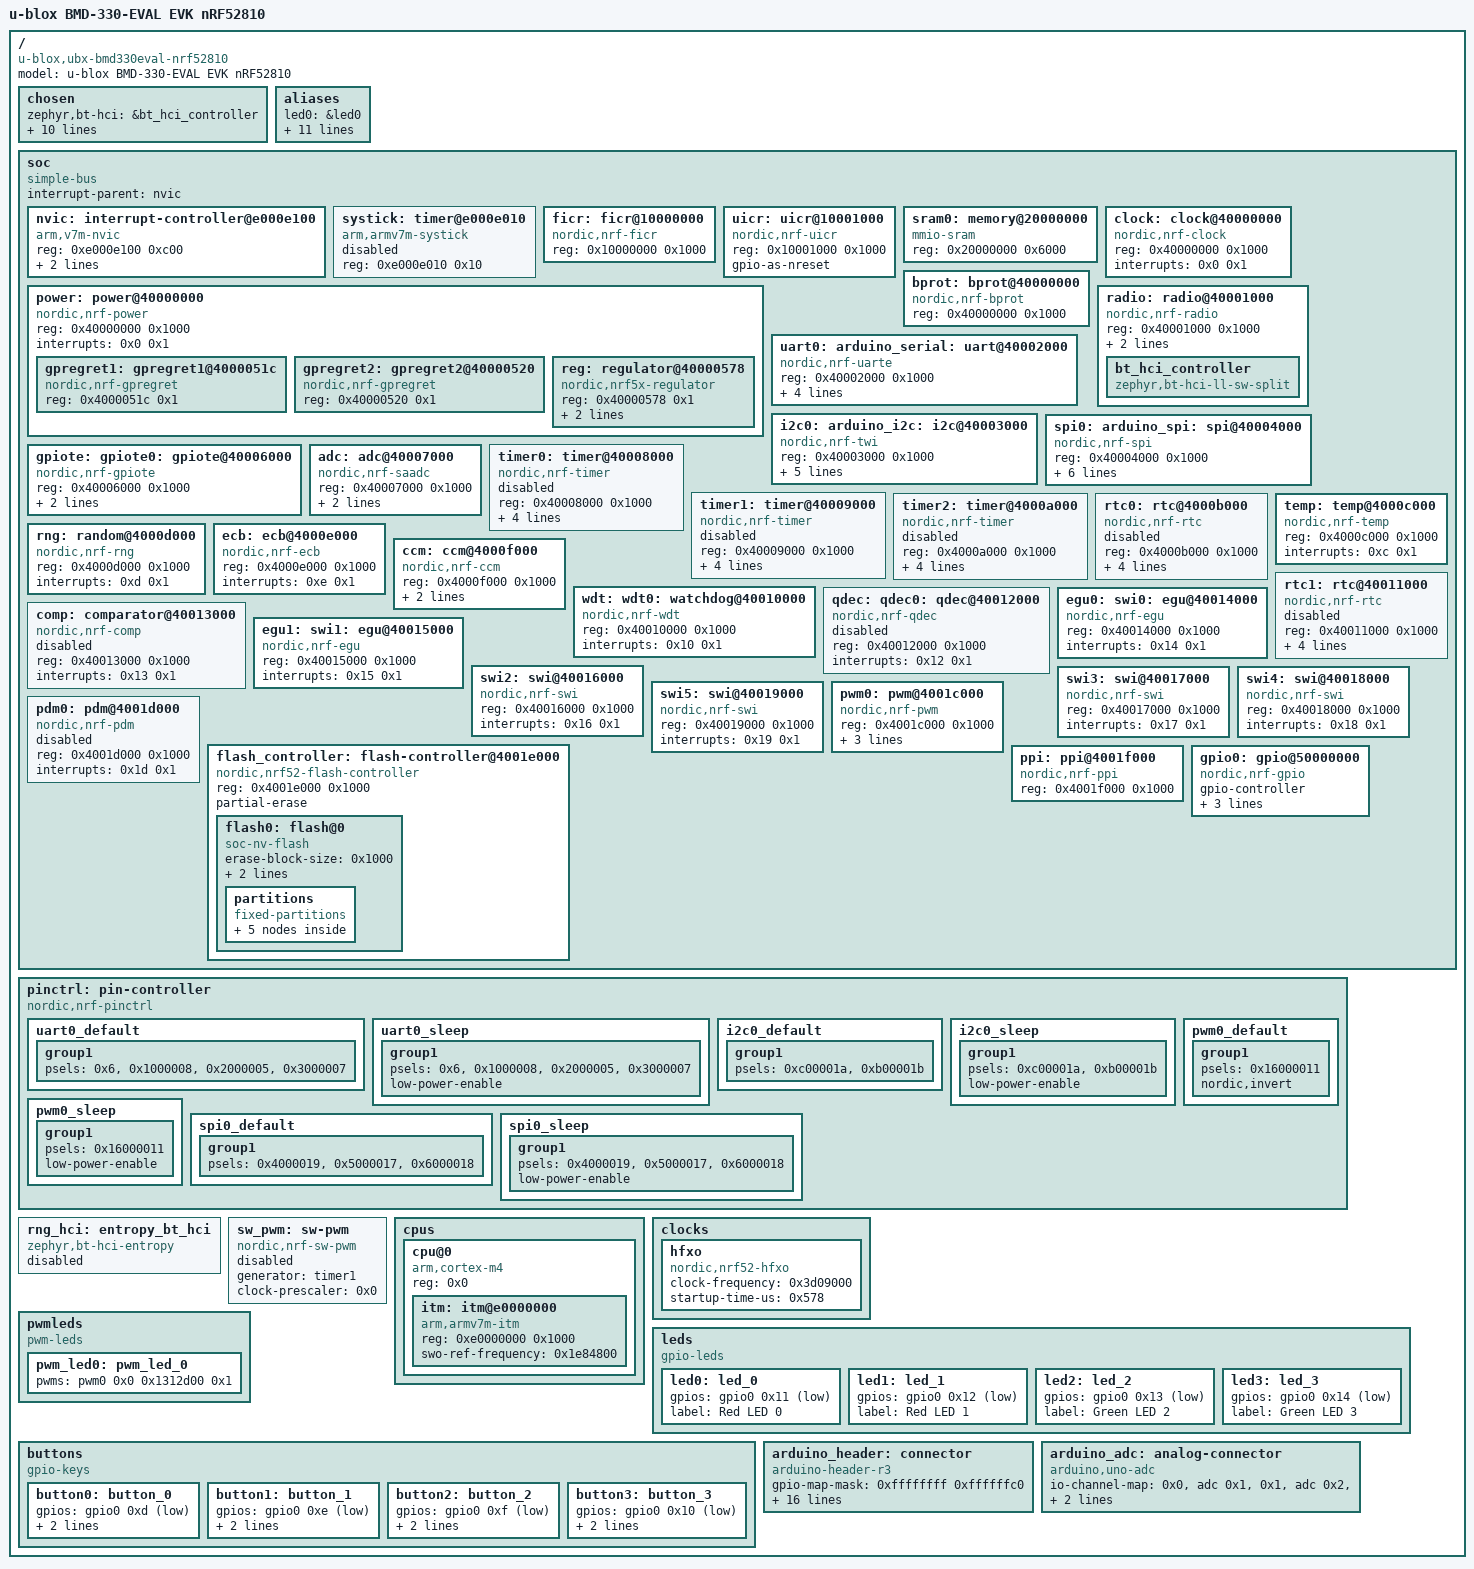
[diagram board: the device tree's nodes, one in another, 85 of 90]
/dts-v1/;

/* node '/' defined in zephyr/dts/common/skeleton.dtsi:9 */
/ {
	#address-cells = < 0x1 >;                      /* in zephyr/dts/common/skeleton.dtsi:10 */
	#size-cells = < 0x1 >;                         /* in zephyr/dts/common/skeleton.dtsi:11 */
	model = "u-blox BMD-330-EVAL EVK nRF52810";    /* in zephyr/boards/u-blox/ubx_bmd330eval/ubx_bmd330eval_nrf52810.dts:14 */
	compatible = "u-blox,ubx-bmd330eval-nrf52810"; /* in zephyr/boards/u-blox/ubx_bmd330eval/ubx_bmd330eval_nrf52810.dts:15 */

	/* node '/chosen' defined in zephyr/dts/common/skeleton.dtsi:13 */
	chosen {
		zephyr,bt-hci = &bt_hci_controller;          /* in zephyr/dts/arm/nordic/nrf52810.dtsi:10 */
		zephyr,entropy = &rng;                       /* in zephyr/dts/arm/nordic/nrf52810.dtsi:11 */
		zephyr,flash-controller = &flash_controller; /* in zephyr/dts/arm/nordic/nrf52810.dtsi:12 */
		zephyr,console = &uart0;                     /* in zephyr/boards/u-blox/ubx_bmd330eval/ubx_bmd330eval_nrf52810.dts:18 */
		zephyr,shell-uart = &uart0;                  /* in zephyr/boards/u-blox/ubx_bmd330eval/ubx_bmd330eval_nrf52810.dts:19 */
		zephyr,uart-mcumgr = &uart0;                 /* in zephyr/boards/u-blox/ubx_bmd330eval/ubx_bmd330eval_nrf52810.dts:20 */
		zephyr,bt-mon-uart = &uart0;                 /* in zephyr/boards/u-blox/ubx_bmd330eval/ubx_bmd330eval_nrf52810.dts:21 */
		zephyr,bt-c2h-uart = &uart0;                 /* in zephyr/boards/u-blox/ubx_bmd330eval/ubx_bmd330eval_nrf52810.dts:22 */
		zephyr,sram = &sram0;                        /* in zephyr/boards/u-blox/ubx_bmd330eval/ubx_bmd330eval_nrf52810.dts:23 */
		zephyr,flash = &flash0;                      /* in zephyr/boards/u-blox/ubx_bmd330eval/ubx_bmd330eval_nrf52810.dts:24 */
		zephyr,code-partition = &slot0_partition;    /* in zephyr/boards/u-blox/ubx_bmd330eval/ubx_bmd330eval_nrf52810.dts:25 */
	};

	/* node '/aliases' defined in zephyr/dts/common/skeleton.dtsi:15 */
	aliases {
		led0 = &led0;               /* in zephyr/boards/u-blox/ubx_bmd330eval/ubx_bmd330eval_nrf52810.dts:130 */
		led1 = &led1;               /* in zephyr/boards/u-blox/ubx_bmd330eval/ubx_bmd330eval_nrf52810.dts:131 */
		led2 = &led2;               /* in zephyr/boards/u-blox/ubx_bmd330eval/ubx_bmd330eval_nrf52810.dts:132 */
		led3 = &led3;               /* in zephyr/boards/u-blox/ubx_bmd330eval/ubx_bmd330eval_nrf52810.dts:133 */
		pwm-led0 = &pwm_led0;       /* in zephyr/boards/u-blox/ubx_bmd330eval/ubx_bmd330eval_nrf52810.dts:134 */
		sw0 = &button0;             /* in zephyr/boards/u-blox/ubx_bmd330eval/ubx_bmd330eval_nrf52810.dts:135 */
		sw1 = &button1;             /* in zephyr/boards/u-blox/ubx_bmd330eval/ubx_bmd330eval_nrf52810.dts:136 */
		sw2 = &button2;             /* in zephyr/boards/u-blox/ubx_bmd330eval/ubx_bmd330eval_nrf52810.dts:137 */
		sw3 = &button3;             /* in zephyr/boards/u-blox/ubx_bmd330eval/ubx_bmd330eval_nrf52810.dts:138 */
		mcuboot-button0 = &button0; /* in zephyr/boards/u-blox/ubx_bmd330eval/ubx_bmd330eval_nrf52810.dts:139 */
		mcuboot-led0 = &led0;       /* in zephyr/boards/u-blox/ubx_bmd330eval/ubx_bmd330eval_nrf52810.dts:140 */
		watchdog0 = &wdt0;          /* in zephyr/boards/u-blox/ubx_bmd330eval/ubx_bmd330eval_nrf52810.dts:141 */
	};

	/* node '/soc' defined in zephyr/dts/arm/armv7-m.dtsi:6 */
	soc {
		#address-cells = < 0x1 >;     /* in zephyr/dts/arm/armv7-m.dtsi:7 */
		#size-cells = < 0x1 >;        /* in zephyr/dts/arm/armv7-m.dtsi:8 */
		interrupt-parent = < &nvic >; /* in zephyr/dts/arm/armv7-m.dtsi:10 */
		ranges;                       /* in zephyr/dts/arm/armv7-m.dtsi:11 */
		compatible = "simple-bus";    /* in zephyr/dts/arm/nordic/nrf52810_qfaa.dtsi:21 */

		/* node '/soc/interrupt-controller@e000e100' defined in zephyr/dts/arm/armv7-m.dtsi:13 */
		nvic: interrupt-controller@e000e100 {
			#address-cells = < 0x1 >;            /* in zephyr/dts/arm/armv7-m.dtsi:14 */
			compatible = "arm,v7m-nvic";         /* in zephyr/dts/arm/armv7-m.dtsi:15 */
			reg = < 0xe000e100 0xc00 >;          /* in zephyr/dts/arm/armv7-m.dtsi:16 */
			interrupt-controller;                /* in zephyr/dts/arm/armv7-m.dtsi:17 */
			#interrupt-cells = < 0x2 >;          /* in zephyr/dts/arm/armv7-m.dtsi:18 */
			arm,num-irq-priority-bits = < 0x3 >; /* in zephyr/dts/arm/nordic/nrf52810.dtsi:377 */
			phandle = < 0x1 >;                   /* in zephyr/dts/arm/armv7-m.dtsi:10 */
		};

		/* node '/soc/timer@e000e010' defined in zephyr/dts/arm/armv7-m.dtsi:21 */
		systick: timer@e000e010 {
			compatible = "arm,armv7m-systick"; /* in zephyr/dts/arm/armv7-m.dtsi:22 */
			reg = < 0xe000e010 0x10 >;         /* in zephyr/dts/arm/armv7-m.dtsi:23 */
			status = "disabled";               /* in zephyr/dts/arm/nordic/nrf52810.dtsi:382 */
		};

		/* node '/soc/ficr@10000000' defined in zephyr/dts/arm/nordic/nrf52810.dtsi:44 */
		ficr: ficr@10000000 {
			compatible = "nordic,nrf-ficr"; /* in zephyr/dts/arm/nordic/nrf52810.dtsi:45 */
			reg = < 0x10000000 0x1000 >;    /* in zephyr/dts/arm/nordic/nrf52810.dtsi:46 */
			#nordic,ficr-cells = < 0x1 >;   /* in zephyr/dts/arm/nordic/nrf52810.dtsi:47 */
			status = "okay";                /* in zephyr/dts/arm/nordic/nrf52810.dtsi:48 */
		};

		/* node '/soc/uicr@10001000' defined in zephyr/dts/arm/nordic/nrf52810.dtsi:51 */
		uicr: uicr@10001000 {
			compatible = "nordic,nrf-uicr"; /* in zephyr/dts/arm/nordic/nrf52810.dtsi:52 */
			reg = < 0x10001000 0x1000 >;    /* in zephyr/dts/arm/nordic/nrf52810.dtsi:53 */
			status = "okay";                /* in zephyr/dts/arm/nordic/nrf52810.dtsi:54 */
			gpio-as-nreset;                 /* in zephyr/boards/u-blox/ubx_bmd330eval/ubx_bmd330eval_nrf52810.dts:154 */
		};

		/* node '/soc/memory@20000000' defined in zephyr/dts/arm/nordic/nrf52810.dtsi:57 */
		sram0: memory@20000000 {
			compatible = "mmio-sram";           /* in zephyr/dts/arm/nordic/nrf52810.dtsi:58 */
			#address-cells = < 0x1 >;           /* in zephyr/dts/arm/nordic/nrf52810.dtsi:59 */
			#size-cells = < 0x1 >;              /* in zephyr/dts/arm/nordic/nrf52810.dtsi:60 */
			reg = < 0x20000000 0x6000 >;        /* in zephyr/dts/arm/nordic/nrf52810_qfaa.dtsi:15 */
			ranges = < 0x0 0x20000000 0x6000 >; /* in zephyr/dts/arm/nordic/nrf52810_qfaa.dtsi:16 */
		};

		/* node '/soc/clock@40000000' defined in zephyr/dts/arm/nordic/nrf52810.dtsi:63 */
		clock: clock@40000000 {
			compatible = "nordic,nrf-clock"; /* in zephyr/dts/arm/nordic/nrf52810.dtsi:64 */
			reg = < 0x40000000 0x1000 >;     /* in zephyr/dts/arm/nordic/nrf52810.dtsi:65 */
			interrupts = < 0x0 0x1 >;        /* in zephyr/dts/arm/nordic/nrf52810.dtsi:66 */
			status = "okay";                 /* in zephyr/dts/arm/nordic/nrf52810.dtsi:67 */
		};

		/* node '/soc/power@40000000' defined in zephyr/dts/arm/nordic/nrf52810.dtsi:70 */
		power: power@40000000 {
			compatible = "nordic,nrf-power"; /* in zephyr/dts/arm/nordic/nrf52810.dtsi:71 */
			reg = < 0x40000000 0x1000 >;     /* in zephyr/dts/arm/nordic/nrf52810.dtsi:72 */
			interrupts = < 0x0 0x1 >;        /* in zephyr/dts/arm/nordic/nrf52810.dtsi:73 */
			status = "okay";                 /* in zephyr/dts/arm/nordic/nrf52810.dtsi:74 */
			#address-cells = < 0x1 >;        /* in zephyr/dts/arm/nordic/nrf52810.dtsi:75 */
			#size-cells = < 0x1 >;           /* in zephyr/dts/arm/nordic/nrf52810.dtsi:76 */

			/* node '/soc/power@40000000/gpregret1@4000051c' defined in zephyr/dts/arm/nordic/nrf52810.dtsi:78 */
			gpregret1: gpregret1@4000051c {
				#address-cells = < 0x1 >;           /* in zephyr/dts/arm/nordic/nrf52810.dtsi:79 */
				#size-cells = < 0x1 >;              /* in zephyr/dts/arm/nordic/nrf52810.dtsi:80 */
				compatible = "nordic,nrf-gpregret"; /* in zephyr/dts/arm/nordic/nrf52810.dtsi:81 */
				reg = < 0x4000051c 0x1 >;           /* in zephyr/dts/arm/nordic/nrf52810.dtsi:82 */
				status = "okay";                    /* in zephyr/dts/arm/nordic/nrf52810.dtsi:83 */
			};

			/* node '/soc/power@40000000/gpregret2@40000520' defined in zephyr/dts/arm/nordic/nrf52810.dtsi:86 */
			gpregret2: gpregret2@40000520 {
				#address-cells = < 0x1 >;           /* in zephyr/dts/arm/nordic/nrf52810.dtsi:87 */
				#size-cells = < 0x1 >;              /* in zephyr/dts/arm/nordic/nrf52810.dtsi:88 */
				compatible = "nordic,nrf-gpregret"; /* in zephyr/dts/arm/nordic/nrf52810.dtsi:89 */
				reg = < 0x40000520 0x1 >;           /* in zephyr/dts/arm/nordic/nrf52810.dtsi:90 */
				status = "okay";                    /* in zephyr/dts/arm/nordic/nrf52810.dtsi:91 */
			};

			/* node '/soc/power@40000000/regulator@40000578' defined in zephyr/dts/arm/nordic/nrf52810.dtsi:94 */
			reg: regulator@40000578 {
				compatible = "nordic,nrf5x-regulator"; /* in zephyr/dts/arm/nordic/nrf52810.dtsi:95 */
				reg = < 0x40000578 0x1 >;              /* in zephyr/dts/arm/nordic/nrf52810.dtsi:96 */
				regulator-name = "REG";                /* in zephyr/dts/arm/nordic/nrf52810.dtsi:97 */
				regulator-initial-mode = < 0x1 >;      /* in zephyr/boards/u-blox/ubx_bmd330eval/ubx_bmd330eval_nrf52810.dts:146 */
			};
		};

		/* node '/soc/bprot@40000000' defined in zephyr/dts/arm/nordic/nrf52810.dtsi:102 */
		bprot: bprot@40000000 {
			compatible = "nordic,nrf-bprot"; /* in zephyr/dts/arm/nordic/nrf52810.dtsi:103 */
			reg = < 0x40000000 0x1000 >;     /* in zephyr/dts/arm/nordic/nrf52810.dtsi:104 */
			status = "okay";                 /* in zephyr/dts/arm/nordic/nrf52810.dtsi:105 */
		};

		/* node '/soc/radio@40001000' defined in zephyr/dts/arm/nordic/nrf52810.dtsi:108 */
		radio: radio@40001000 {
			compatible = "nordic,nrf-radio"; /* in zephyr/dts/arm/nordic/nrf52810.dtsi:109 */
			reg = < 0x40001000 0x1000 >;     /* in zephyr/dts/arm/nordic/nrf52810.dtsi:110 */
			interrupts = < 0x1 0x1 >;        /* in zephyr/dts/arm/nordic/nrf52810.dtsi:111 */
			status = "okay";                 /* in zephyr/dts/arm/nordic/nrf52810.dtsi:112 */
			ble-2mbps-supported;             /* in zephyr/dts/arm/nordic/nrf52810.dtsi:113 */

			/* node '/soc/radio@40001000/bt_hci_controller' defined in zephyr/dts/arm/nordic/nrf52810.dtsi:118 */
			bt_hci_controller: bt_hci_controller {
				compatible = "zephyr,bt-hci-ll-sw-split"; /* in zephyr/dts/arm/nordic/nrf52810.dtsi:119 */
				status = "okay";                          /* in zephyr/dts/arm/nordic/nrf52810.dtsi:120 */
			};
		};

		/* node '/soc/uart@40002000' defined in zephyr/dts/arm/nordic/nrf52810.dtsi:124 */
		uart0: arduino_serial: uart@40002000 {
			reg = < 0x40002000 0x1000 >;     /* in zephyr/dts/arm/nordic/nrf52810.dtsi:128 */
			interrupts = < 0x2 0x1 >;        /* in zephyr/dts/arm/nordic/nrf52810.dtsi:129 */
			compatible = "nordic,nrf-uarte"; /* in zephyr/boards/u-blox/ubx_bmd330eval/ubx_bmd330eval_nrf52810.dts:166 */
			status = "okay";                 /* in zephyr/boards/u-blox/ubx_bmd330eval/ubx_bmd330eval_nrf52810.dts:167 */
			current-speed = < 0x1c200 >;     /* in zephyr/boards/u-blox/ubx_bmd330eval/ubx_bmd330eval_nrf52810.dts:168 */
			pinctrl-0 = < &uart0_default >;  /* in zephyr/boards/u-blox/ubx_bmd330eval/ubx_bmd330eval_nrf52810.dts:169 */
			pinctrl-1 = < &uart0_sleep >;    /* in zephyr/boards/u-blox/ubx_bmd330eval/ubx_bmd330eval_nrf52810.dts:170 */
			pinctrl-names = "default",
			                "sleep";         /* in zephyr/boards/u-blox/ubx_bmd330eval/ubx_bmd330eval_nrf52810.dts:171 */
		};

		/* node '/soc/i2c@40003000' defined in zephyr/dts/arm/nordic/nrf52810.dtsi:133 */
		i2c0: arduino_i2c: i2c@40003000 {
			#address-cells = < 0x1 >;      /* in zephyr/dts/arm/nordic/nrf52810.dtsi:142 */
			#size-cells = < 0x0 >;         /* in zephyr/dts/arm/nordic/nrf52810.dtsi:143 */
			reg = < 0x40003000 0x1000 >;   /* in zephyr/dts/arm/nordic/nrf52810.dtsi:144 */
			interrupts = < 0x3 0x1 >;      /* in zephyr/dts/arm/nordic/nrf52810.dtsi:145 */
			easydma-maxcnt-bits = < 0xa >; /* in zephyr/dts/arm/nordic/nrf52810.dtsi:146 */
			zephyr,pm-device-runtime-auto; /* in zephyr/dts/arm/nordic/nrf52810.dtsi:148 */
			compatible = "nordic,nrf-twi"; /* in zephyr/boards/u-blox/ubx_bmd330eval/ubx_bmd330eval_nrf52810.dts:175 */
			status = "okay";               /* in zephyr/boards/u-blox/ubx_bmd330eval/ubx_bmd330eval_nrf52810.dts:176 */
			pinctrl-0 = < &i2c0_default >; /* in zephyr/boards/u-blox/ubx_bmd330eval/ubx_bmd330eval_nrf52810.dts:177 */
			pinctrl-1 = < &i2c0_sleep >;   /* in zephyr/boards/u-blox/ubx_bmd330eval/ubx_bmd330eval_nrf52810.dts:178 */
			pinctrl-names = "default",
			                "sleep";       /* in zephyr/boards/u-blox/ubx_bmd330eval/ubx_bmd330eval_nrf52810.dts:179 */
		};

		/* node '/soc/spi@40004000' defined in zephyr/dts/arm/nordic/nrf52810.dtsi:151 */
		spi0: arduino_spi: spi@40004000 {
			#address-cells = < 0x1 >;                /* in zephyr/dts/arm/nordic/nrf52810.dtsi:160 */
			#size-cells = < 0x0 >;                   /* in zephyr/dts/arm/nordic/nrf52810.dtsi:161 */
			reg = < 0x40004000 0x1000 >;             /* in zephyr/dts/arm/nordic/nrf52810.dtsi:162 */
			interrupts = < 0x4 0x1 >;                /* in zephyr/dts/arm/nordic/nrf52810.dtsi:163 */
			max-frequency = < 0x7a1200 >;            /* in zephyr/dts/arm/nordic/nrf52810.dtsi:164 */
			easydma-maxcnt-bits = < 0xa >;           /* in zephyr/dts/arm/nordic/nrf52810.dtsi:165 */
			compatible = "nordic,nrf-spi";           /* in zephyr/boards/u-blox/ubx_bmd330eval/ubx_bmd330eval_nrf52810.dts:190 */
			status = "okay";                         /* in zephyr/boards/u-blox/ubx_bmd330eval/ubx_bmd330eval_nrf52810.dts:191 */
			cs-gpios = < &arduino_header 0x10 0x1 >; /* in zephyr/boards/u-blox/ubx_bmd330eval/ubx_bmd330eval_nrf52810.dts:192 */
			pinctrl-0 = < &spi0_default >;           /* in zephyr/boards/u-blox/ubx_bmd330eval/ubx_bmd330eval_nrf52810.dts:193 */
			pinctrl-1 = < &spi0_sleep >;             /* in zephyr/boards/u-blox/ubx_bmd330eval/ubx_bmd330eval_nrf52810.dts:194 */
			pinctrl-names = "default",
			                "sleep";                 /* in zephyr/boards/u-blox/ubx_bmd330eval/ubx_bmd330eval_nrf52810.dts:195 */
		};

		/* node '/soc/gpiote@40006000' defined in zephyr/dts/arm/nordic/nrf52810.dtsi:169 */
		gpiote: gpiote0: gpiote@40006000 {
			compatible = "nordic,nrf-gpiote"; /* in zephyr/dts/arm/nordic/nrf52810.dtsi:170 */
			reg = < 0x40006000 0x1000 >;      /* in zephyr/dts/arm/nordic/nrf52810.dtsi:171 */
			interrupts = < 0x6 0x5 >;         /* in zephyr/dts/arm/nordic/nrf52810.dtsi:172 */
			instance = < 0x0 >;               /* in zephyr/dts/arm/nordic/nrf52810.dtsi:174 */
			status = "okay";                  /* in zephyr/boards/u-blox/ubx_bmd330eval/ubx_bmd330eval_nrf52810.dts:158 */
			phandle = < 0xb >;                /* in zephyr/dts/arm/nordic/nrf52810.dtsi:371 */
		};

		/* node '/soc/adc@40007000' defined in zephyr/dts/arm/nordic/nrf52810.dtsi:177 */
		adc: adc@40007000 {
			compatible = "nordic,nrf-saadc"; /* in zephyr/dts/arm/nordic/nrf52810.dtsi:178 */
			reg = < 0x40007000 0x1000 >;     /* in zephyr/dts/arm/nordic/nrf52810.dtsi:179 */
			interrupts = < 0x7 0x1 >;        /* in zephyr/dts/arm/nordic/nrf52810.dtsi:180 */
			#io-channel-cells = < 0x1 >;     /* in zephyr/dts/arm/nordic/nrf52810.dtsi:182 */
			zephyr,pm-device-runtime-auto;   /* in zephyr/dts/arm/nordic/nrf52810.dtsi:183 */
			status = "okay";                 /* in zephyr/boards/u-blox/ubx_bmd330eval/ubx_bmd330eval_nrf52810.dts:150 */
			phandle = < 0xf >;               /* in zephyr/boards/u-blox/ubx_bmd330eval/ubx_bmd330eval_nrf52810.dts:120 */
		};

		/* node '/soc/timer@40008000' defined in zephyr/dts/arm/nordic/nrf52810.dtsi:186 */
		timer0: timer@40008000 {
			compatible = "nordic,nrf-timer"; /* in zephyr/dts/arm/nordic/nrf52810.dtsi:187 */
			status = "disabled";             /* in zephyr/dts/arm/nordic/nrf52810.dtsi:188 */
			reg = < 0x40008000 0x1000 >;     /* in zephyr/dts/arm/nordic/nrf52810.dtsi:189 */
			cc-num = < 0x4 >;                /* in zephyr/dts/arm/nordic/nrf52810.dtsi:190 */
			max-bit-width = < 0x20 >;        /* in zephyr/dts/arm/nordic/nrf52810.dtsi:191 */
			interrupts = < 0x8 0x1 >;        /* in zephyr/dts/arm/nordic/nrf52810.dtsi:192 */
			prescaler = < 0x0 >;             /* in zephyr/dts/arm/nordic/nrf52810.dtsi:193 */
		};

		/* node '/soc/timer@40009000' defined in zephyr/dts/arm/nordic/nrf52810.dtsi:196 */
		timer1: timer@40009000 {
			compatible = "nordic,nrf-timer"; /* in zephyr/dts/arm/nordic/nrf52810.dtsi:197 */
			status = "disabled";             /* in zephyr/dts/arm/nordic/nrf52810.dtsi:198 */
			reg = < 0x40009000 0x1000 >;     /* in zephyr/dts/arm/nordic/nrf52810.dtsi:199 */
			cc-num = < 0x4 >;                /* in zephyr/dts/arm/nordic/nrf52810.dtsi:200 */
			max-bit-width = < 0x20 >;        /* in zephyr/dts/arm/nordic/nrf52810.dtsi:201 */
			interrupts = < 0x9 0x1 >;        /* in zephyr/dts/arm/nordic/nrf52810.dtsi:202 */
			prescaler = < 0x0 >;             /* in zephyr/dts/arm/nordic/nrf52810.dtsi:203 */
			phandle = < 0xc >;               /* in zephyr/dts/vendor/nordic/nrf_common.dtsi:42 */
		};

		/* node '/soc/timer@4000a000' defined in zephyr/dts/arm/nordic/nrf52810.dtsi:206 */
		timer2: timer@4000a000 {
			compatible = "nordic,nrf-timer"; /* in zephyr/dts/arm/nordic/nrf52810.dtsi:207 */
			status = "disabled";             /* in zephyr/dts/arm/nordic/nrf52810.dtsi:208 */
			reg = < 0x4000a000 0x1000 >;     /* in zephyr/dts/arm/nordic/nrf52810.dtsi:209 */
			cc-num = < 0x4 >;                /* in zephyr/dts/arm/nordic/nrf52810.dtsi:210 */
			max-bit-width = < 0x20 >;        /* in zephyr/dts/arm/nordic/nrf52810.dtsi:211 */
			interrupts = < 0xa 0x1 >;        /* in zephyr/dts/arm/nordic/nrf52810.dtsi:212 */
			prescaler = < 0x0 >;             /* in zephyr/dts/arm/nordic/nrf52810.dtsi:213 */
		};

		/* node '/soc/rtc@4000b000' defined in zephyr/dts/arm/nordic/nrf52810.dtsi:216 */
		rtc0: rtc@4000b000 {
			compatible = "nordic,nrf-rtc"; /* in zephyr/dts/arm/nordic/nrf52810.dtsi:217 */
			reg = < 0x4000b000 0x1000 >;   /* in zephyr/dts/arm/nordic/nrf52810.dtsi:218 */
			cc-num = < 0x3 >;              /* in zephyr/dts/arm/nordic/nrf52810.dtsi:219 */
			interrupts = < 0xb 0x1 >;      /* in zephyr/dts/arm/nordic/nrf52810.dtsi:220 */
			status = "disabled";           /* in zephyr/dts/arm/nordic/nrf52810.dtsi:221 */
			clock-frequency = < 0x8000 >;  /* in zephyr/dts/arm/nordic/nrf52810.dtsi:222 */
			prescaler = < 0x1 >;           /* in zephyr/dts/arm/nordic/nrf52810.dtsi:223 */
		};

		/* node '/soc/temp@4000c000' defined in zephyr/dts/arm/nordic/nrf52810.dtsi:226 */
		temp: temp@4000c000 {
			compatible = "nordic,nrf-temp"; /* in zephyr/dts/arm/nordic/nrf52810.dtsi:227 */
			reg = < 0x4000c000 0x1000 >;    /* in zephyr/dts/arm/nordic/nrf52810.dtsi:228 */
			interrupts = < 0xc 0x1 >;       /* in zephyr/dts/arm/nordic/nrf52810.dtsi:229 */
			status = "okay";                /* in zephyr/dts/arm/nordic/nrf52810.dtsi:230 */
		};

		/* node '/soc/random@4000d000' defined in zephyr/dts/arm/nordic/nrf52810.dtsi:233 */
		rng: random@4000d000 {
			compatible = "nordic,nrf-rng"; /* in zephyr/dts/arm/nordic/nrf52810.dtsi:234 */
			reg = < 0x4000d000 0x1000 >;   /* in zephyr/dts/arm/nordic/nrf52810.dtsi:235 */
			interrupts = < 0xd 0x1 >;      /* in zephyr/dts/arm/nordic/nrf52810.dtsi:236 */
			status = "okay";               /* in zephyr/dts/arm/nordic/nrf52810.dtsi:237 */
		};

		/* node '/soc/ecb@4000e000' defined in zephyr/dts/arm/nordic/nrf52810.dtsi:240 */
		ecb: ecb@4000e000 {
			compatible = "nordic,nrf-ecb"; /* in zephyr/dts/arm/nordic/nrf52810.dtsi:241 */
			reg = < 0x4000e000 0x1000 >;   /* in zephyr/dts/arm/nordic/nrf52810.dtsi:242 */
			interrupts = < 0xe 0x1 >;      /* in zephyr/dts/arm/nordic/nrf52810.dtsi:243 */
			status = "okay";               /* in zephyr/dts/arm/nordic/nrf52810.dtsi:244 */
		};

		/* node '/soc/ccm@4000f000' defined in zephyr/dts/arm/nordic/nrf52810.dtsi:247 */
		ccm: ccm@4000f000 {
			compatible = "nordic,nrf-ccm"; /* in zephyr/dts/arm/nordic/nrf52810.dtsi:248 */
			reg = < 0x4000f000 0x1000 >;   /* in zephyr/dts/arm/nordic/nrf52810.dtsi:249 */
			interrupts = < 0xf 0x1 >;      /* in zephyr/dts/arm/nordic/nrf52810.dtsi:250 */
			length-field-length-8-bits;    /* in zephyr/dts/arm/nordic/nrf52810.dtsi:251 */
			status = "okay";               /* in zephyr/dts/arm/nordic/nrf52810.dtsi:252 */
		};

		/* node '/soc/watchdog@40010000' defined in zephyr/dts/arm/nordic/nrf52810.dtsi:255 */
		wdt: wdt0: watchdog@40010000 {
			compatible = "nordic,nrf-wdt"; /* in zephyr/dts/arm/nordic/nrf52810.dtsi:256 */
			reg = < 0x40010000 0x1000 >;   /* in zephyr/dts/arm/nordic/nrf52810.dtsi:257 */
			interrupts = < 0x10 0x1 >;     /* in zephyr/dts/arm/nordic/nrf52810.dtsi:258 */
			status = "okay";               /* in zephyr/dts/arm/nordic/nrf52810.dtsi:259 */
		};

		/* node '/soc/rtc@40011000' defined in zephyr/dts/arm/nordic/nrf52810.dtsi:262 */
		rtc1: rtc@40011000 {
			compatible = "nordic,nrf-rtc"; /* in zephyr/dts/arm/nordic/nrf52810.dtsi:263 */
			reg = < 0x40011000 0x1000 >;   /* in zephyr/dts/arm/nordic/nrf52810.dtsi:264 */
			cc-num = < 0x4 >;              /* in zephyr/dts/arm/nordic/nrf52810.dtsi:265 */
			interrupts = < 0x11 0x1 >;     /* in zephyr/dts/arm/nordic/nrf52810.dtsi:266 */
			status = "disabled";           /* in zephyr/dts/arm/nordic/nrf52810.dtsi:267 */
			clock-frequency = < 0x8000 >;  /* in zephyr/dts/arm/nordic/nrf52810.dtsi:268 */
			prescaler = < 0x1 >;           /* in zephyr/dts/arm/nordic/nrf52810.dtsi:269 */
		};

		/* node '/soc/qdec@40012000' defined in zephyr/dts/arm/nordic/nrf52810.dtsi:272 */
		qdec: qdec0: qdec@40012000 {
			compatible = "nordic,nrf-qdec"; /* in zephyr/dts/arm/nordic/nrf52810.dtsi:273 */
			reg = < 0x40012000 0x1000 >;    /* in zephyr/dts/arm/nordic/nrf52810.dtsi:274 */
			interrupts = < 0x12 0x1 >;      /* in zephyr/dts/arm/nordic/nrf52810.dtsi:275 */
			status = "disabled";            /* in zephyr/dts/arm/nordic/nrf52810.dtsi:276 */
		};

		/* node '/soc/comparator@40013000' defined in zephyr/dts/arm/nordic/nrf52810.dtsi:279 */
		comp: comparator@40013000 {
			compatible = "nordic,nrf-comp"; /* in zephyr/dts/arm/nordic/nrf52810.dtsi:280 */
			reg = < 0x40013000 0x1000 >;    /* in zephyr/dts/arm/nordic/nrf52810.dtsi:281 */
			interrupts = < 0x13 0x1 >;      /* in zephyr/dts/arm/nordic/nrf52810.dtsi:282 */
			status = "disabled";            /* in zephyr/dts/arm/nordic/nrf52810.dtsi:283 */
		};

		/* node '/soc/egu@40014000' defined in zephyr/dts/arm/nordic/nrf52810.dtsi:286 */
		egu0: swi0: egu@40014000 {
			compatible = "nordic,nrf-egu",
			             "nordic,nrf-swi"; /* in zephyr/dts/arm/nordic/nrf52810.dtsi:287 */
			reg = < 0x40014000 0x1000 >;   /* in zephyr/dts/arm/nordic/nrf52810.dtsi:288 */
			interrupts = < 0x14 0x1 >;     /* in zephyr/dts/arm/nordic/nrf52810.dtsi:289 */
			status = "okay";               /* in zephyr/dts/arm/nordic/nrf52810.dtsi:290 */
		};

		/* node '/soc/egu@40015000' defined in zephyr/dts/arm/nordic/nrf52810.dtsi:293 */
		egu1: swi1: egu@40015000 {
			compatible = "nordic,nrf-egu",
			             "nordic,nrf-swi"; /* in zephyr/dts/arm/nordic/nrf52810.dtsi:294 */
			reg = < 0x40015000 0x1000 >;   /* in zephyr/dts/arm/nordic/nrf52810.dtsi:295 */
			interrupts = < 0x15 0x1 >;     /* in zephyr/dts/arm/nordic/nrf52810.dtsi:296 */
			status = "okay";               /* in zephyr/dts/arm/nordic/nrf52810.dtsi:297 */
		};

		/* node '/soc/swi@40016000' defined in zephyr/dts/arm/nordic/nrf52810.dtsi:300 */
		swi2: swi@40016000 {
			compatible = "nordic,nrf-swi"; /* in zephyr/dts/arm/nordic/nrf52810.dtsi:301 */
			reg = < 0x40016000 0x1000 >;   /* in zephyr/dts/arm/nordic/nrf52810.dtsi:302 */
			interrupts = < 0x16 0x1 >;     /* in zephyr/dts/arm/nordic/nrf52810.dtsi:303 */
			status = "okay";               /* in zephyr/dts/arm/nordic/nrf52810.dtsi:304 */
		};

		/* node '/soc/swi@40017000' defined in zephyr/dts/arm/nordic/nrf52810.dtsi:307 */
		swi3: swi@40017000 {
			compatible = "nordic,nrf-swi"; /* in zephyr/dts/arm/nordic/nrf52810.dtsi:308 */
			reg = < 0x40017000 0x1000 >;   /* in zephyr/dts/arm/nordic/nrf52810.dtsi:309 */
			interrupts = < 0x17 0x1 >;     /* in zephyr/dts/arm/nordic/nrf52810.dtsi:310 */
			status = "okay";               /* in zephyr/dts/arm/nordic/nrf52810.dtsi:311 */
		};

		/* node '/soc/swi@40018000' defined in zephyr/dts/arm/nordic/nrf52810.dtsi:314 */
		swi4: swi@40018000 {
			compatible = "nordic,nrf-swi"; /* in zephyr/dts/arm/nordic/nrf52810.dtsi:315 */
			reg = < 0x40018000 0x1000 >;   /* in zephyr/dts/arm/nordic/nrf52810.dtsi:316 */
			interrupts = < 0x18 0x1 >;     /* in zephyr/dts/arm/nordic/nrf52810.dtsi:317 */
			status = "okay";               /* in zephyr/dts/arm/nordic/nrf52810.dtsi:318 */
		};

		/* node '/soc/swi@40019000' defined in zephyr/dts/arm/nordic/nrf52810.dtsi:321 */
		swi5: swi@40019000 {
			compatible = "nordic,nrf-swi"; /* in zephyr/dts/arm/nordic/nrf52810.dtsi:322 */
			reg = < 0x40019000 0x1000 >;   /* in zephyr/dts/arm/nordic/nrf52810.dtsi:323 */
			interrupts = < 0x19 0x1 >;     /* in zephyr/dts/arm/nordic/nrf52810.dtsi:324 */
			status = "okay";               /* in zephyr/dts/arm/nordic/nrf52810.dtsi:325 */
		};

		/* node '/soc/pwm@4001c000' defined in zephyr/dts/arm/nordic/nrf52810.dtsi:328 */
		pwm0: pwm@4001c000 {
			compatible = "nordic,nrf-pwm"; /* in zephyr/dts/arm/nordic/nrf52810.dtsi:329 */
			reg = < 0x4001c000 0x1000 >;   /* in zephyr/dts/arm/nordic/nrf52810.dtsi:330 */
			interrupts = < 0x1c 0x1 >;     /* in zephyr/dts/arm/nordic/nrf52810.dtsi:331 */
			#pwm-cells = < 0x3 >;          /* in zephyr/dts/arm/nordic/nrf52810.dtsi:333 */
			status = "okay";               /* in zephyr/boards/u-blox/ubx_bmd330eval/ubx_bmd330eval_nrf52810.dts:183 */
			pinctrl-0 = < &pwm0_default >; /* in zephyr/boards/u-blox/ubx_bmd330eval/ubx_bmd330eval_nrf52810.dts:184 */
			pinctrl-1 = < &pwm0_sleep >;   /* in zephyr/boards/u-blox/ubx_bmd330eval/ubx_bmd330eval_nrf52810.dts:185 */
			pinctrl-names = "default",
			                "sleep";       /* in zephyr/boards/u-blox/ubx_bmd330eval/ubx_bmd330eval_nrf52810.dts:186 */
			phandle = < 0xe >;             /* in zephyr/boards/u-blox/ubx_bmd330eval/ubx_bmd330eval_nrf52810.dts:56 */
		};

		/* node '/soc/pdm@4001d000' defined in zephyr/dts/arm/nordic/nrf52810.dtsi:336 */
		pdm0: pdm@4001d000 {
			compatible = "nordic,nrf-pdm"; /* in zephyr/dts/arm/nordic/nrf52810.dtsi:337 */
			reg = < 0x4001d000 0x1000 >;   /* in zephyr/dts/arm/nordic/nrf52810.dtsi:338 */
			interrupts = < 0x1d 0x1 >;     /* in zephyr/dts/arm/nordic/nrf52810.dtsi:339 */
			status = "disabled";           /* in zephyr/dts/arm/nordic/nrf52810.dtsi:340 */
		};

		/* node '/soc/flash-controller@4001e000' defined in zephyr/dts/arm/nordic/nrf52810.dtsi:343 */
		flash_controller: flash-controller@4001e000 {
			compatible = "nordic,nrf52-flash-controller"; /* in zephyr/dts/arm/nordic/nrf52810.dtsi:344 */
			reg = < 0x4001e000 0x1000 >;                  /* in zephyr/dts/arm/nordic/nrf52810.dtsi:345 */
			partial-erase;                                /* in zephyr/dts/arm/nordic/nrf52810.dtsi:346 */
			#address-cells = < 0x1 >;                     /* in zephyr/dts/arm/nordic/nrf52810.dtsi:348 */
			#size-cells = < 0x1 >;                        /* in zephyr/dts/arm/nordic/nrf52810.dtsi:349 */

			/* node '/soc/flash-controller@4001e000/flash@0' defined in zephyr/dts/arm/nordic/nrf52810.dtsi:351 */
			flash0: flash@0 {
				compatible = "soc-nv-flash";   /* in zephyr/dts/arm/nordic/nrf52810.dtsi:352 */
				erase-block-size = < 0x1000 >; /* in zephyr/dts/arm/nordic/nrf52810.dtsi:353 */
				write-block-size = < 0x4 >;    /* in zephyr/dts/arm/nordic/nrf52810.dtsi:354 */
				reg = < 0x0 0x30000 >;         /* in zephyr/dts/arm/nordic/nrf52810_qfaa.dtsi:11 */

				/* node '/soc/flash-controller@4001e000/flash@0/partitions' defined in zephyr/boards/u-blox/ubx_bmd330eval/ubx_bmd330eval_nrf52810.dts:199 */
				partitions {
					compatible = "fixed-partitions"; /* in zephyr/boards/u-blox/ubx_bmd330eval/ubx_bmd330eval_nrf52810.dts:200 */
					#address-cells = < 0x1 >;        /* in zephyr/boards/u-blox/ubx_bmd330eval/ubx_bmd330eval_nrf52810.dts:201 */
					#size-cells = < 0x1 >;           /* in zephyr/boards/u-blox/ubx_bmd330eval/ubx_bmd330eval_nrf52810.dts:202 */

					/* node '/soc/flash-controller@4001e000/flash@0/partitions/partition@0' defined in zephyr/boards/u-blox/ubx_bmd330eval/ubx_bmd330eval_nrf52810.dts:204 */
					boot_partition: partition@0 {
						label = "mcuboot";    /* in zephyr/boards/u-blox/ubx_bmd330eval/ubx_bmd330eval_nrf52810.dts:205 */
						reg = < 0x0 0xc000 >; /* in zephyr/boards/u-blox/ubx_bmd330eval/ubx_bmd330eval_nrf52810.dts:206 */
					};

					/* node '/soc/flash-controller@4001e000/flash@0/partitions/partition@c000' defined in zephyr/boards/u-blox/ubx_bmd330eval/ubx_bmd330eval_nrf52810.dts:209 */
					slot0_partition: partition@c000 {
						label = "image-0";       /* in zephyr/boards/u-blox/ubx_bmd330eval/ubx_bmd330eval_nrf52810.dts:210 */
						reg = < 0xc000 0xd000 >; /* in zephyr/boards/u-blox/ubx_bmd330eval/ubx_bmd330eval_nrf52810.dts:211 */
					};

					/* node '/soc/flash-controller@4001e000/flash@0/partitions/partition@19000' defined in zephyr/boards/u-blox/ubx_bmd330eval/ubx_bmd330eval_nrf52810.dts:214 */
					slot1_partition: partition@19000 {
						label = "image-1";        /* in zephyr/boards/u-blox/ubx_bmd330eval/ubx_bmd330eval_nrf52810.dts:215 */
						reg = < 0x19000 0xd000 >; /* in zephyr/boards/u-blox/ubx_bmd330eval/ubx_bmd330eval_nrf52810.dts:216 */
					};

					/* node '/soc/flash-controller@4001e000/flash@0/partitions/partition@26000' defined in zephyr/boards/u-blox/ubx_bmd330eval/ubx_bmd330eval_nrf52810.dts:219 */
					scratch_partition: partition@26000 {
						label = "image-scratch";  /* in zephyr/boards/u-blox/ubx_bmd330eval/ubx_bmd330eval_nrf52810.dts:220 */
						reg = < 0x26000 0x3000 >; /* in zephyr/boards/u-blox/ubx_bmd330eval/ubx_bmd330eval_nrf52810.dts:221 */
					};

					/* node '/soc/flash-controller@4001e000/flash@0/partitions/partition@29000' defined in zephyr/boards/u-blox/ubx_bmd330eval/ubx_bmd330eval_nrf52810.dts:224 */
					storage_partition: partition@29000 {
						label = "storage";        /* in zephyr/boards/u-blox/ubx_bmd330eval/ubx_bmd330eval_nrf52810.dts:225 */
						reg = < 0x29000 0x7000 >; /* in zephyr/boards/u-blox/ubx_bmd330eval/ubx_bmd330eval_nrf52810.dts:226 */
					};
				};
			};
		};

		/* node '/soc/ppi@4001f000' defined in zephyr/dts/arm/nordic/nrf52810.dtsi:358 */
		ppi: ppi@4001f000 {
			compatible = "nordic,nrf-ppi"; /* in zephyr/dts/arm/nordic/nrf52810.dtsi:359 */
			reg = < 0x4001f000 0x1000 >;   /* in zephyr/dts/arm/nordic/nrf52810.dtsi:360 */
			status = "okay";               /* in zephyr/dts/arm/nordic/nrf52810.dtsi:361 */
		};

		/* node '/soc/gpio@50000000' defined in zephyr/dts/arm/nordic/nrf52810.dtsi:364 */
		gpio0: gpio@50000000 {
			compatible = "nordic,nrf-gpio"; /* in zephyr/dts/arm/nordic/nrf52810.dtsi:365 */
			gpio-controller;                /* in zephyr/dts/arm/nordic/nrf52810.dtsi:366 */
			reg = < 0x50000000 0x1000 >;    /* in zephyr/dts/arm/nordic/nrf52810.dtsi:367 */
			#gpio-cells = < 0x2 >;          /* in zephyr/dts/arm/nordic/nrf52810.dtsi:368 */
			port = < 0x0 >;                 /* in zephyr/dts/arm/nordic/nrf52810.dtsi:370 */
			gpiote-instance = < &gpiote >;  /* in zephyr/dts/arm/nordic/nrf52810.dtsi:371 */
			status = "okay";                /* in zephyr/boards/u-blox/ubx_bmd330eval/ubx_bmd330eval_nrf52810.dts:162 */
			phandle = < 0xd >;              /* in zephyr/boards/u-blox/ubx_bmd330eval/ubx_bmd330eval_nrf52810.dts:32 */
		};
	};

	/* node '/pin-controller' defined in zephyr/dts/vendor/nordic/nrf_common.dtsi:26 */
	pinctrl: pin-controller {
		compatible = "nordic,nrf-pinctrl"; /* in zephyr/dts/vendor/nordic/nrf_common.dtsi:31 */

		/* node '/pin-controller/uart0_default' defined in zephyr/boards/u-blox/ubx_bmd330eval/ubx_bmd330eval_nrf52810-pinctrl.dtsi:7 */
		uart0_default: uart0_default {
			phandle = < 0x2 >; /* in zephyr/boards/u-blox/ubx_bmd330eval/ubx_bmd330eval_nrf52810.dts:169 */

			/* node '/pin-controller/uart0_default/group1' defined in zephyr/boards/u-blox/ubx_bmd330eval/ubx_bmd330eval_nrf52810-pinctrl.dtsi:8 */
			group1 {
				psels = < 0x6 >,
				        < 0x1000008 >,
				        < 0x2000005 >,
				        < 0x3000007 >; /* in zephyr/boards/u-blox/ubx_bmd330eval/ubx_bmd330eval_nrf52810-pinctrl.dtsi:9 */
			};
		};

		/* node '/pin-controller/uart0_sleep' defined in zephyr/boards/u-blox/ubx_bmd330eval/ubx_bmd330eval_nrf52810-pinctrl.dtsi:16 */
		uart0_sleep: uart0_sleep {
			phandle = < 0x3 >; /* in zephyr/boards/u-blox/ubx_bmd330eval/ubx_bmd330eval_nrf52810.dts:170 */

			/* node '/pin-controller/uart0_sleep/group1' defined in zephyr/boards/u-blox/ubx_bmd330eval/ubx_bmd330eval_nrf52810-pinctrl.dtsi:17 */
			group1 {
				psels = < 0x6 >,
				        < 0x1000008 >,
				        < 0x2000005 >,
				        < 0x3000007 >; /* in zephyr/boards/u-blox/ubx_bmd330eval/ubx_bmd330eval_nrf52810-pinctrl.dtsi:18 */
				low-power-enable;      /* in zephyr/boards/u-blox/ubx_bmd330eval/ubx_bmd330eval_nrf52810-pinctrl.dtsi:22 */
			};
		};

		/* node '/pin-controller/i2c0_default' defined in zephyr/boards/u-blox/ubx_bmd330eval/ubx_bmd330eval_nrf52810-pinctrl.dtsi:26 */
		i2c0_default: i2c0_default {
			phandle = < 0x4 >; /* in zephyr/boards/u-blox/ubx_bmd330eval/ubx_bmd330eval_nrf52810.dts:177 */

			/* node '/pin-controller/i2c0_default/group1' defined in zephyr/boards/u-blox/ubx_bmd330eval/ubx_bmd330eval_nrf52810-pinctrl.dtsi:27 */
			group1 {
				psels = < 0xc00001a >,
				        < 0xb00001b >; /* in zephyr/boards/u-blox/ubx_bmd330eval/ubx_bmd330eval_nrf52810-pinctrl.dtsi:28 */
			};
		};

		/* node '/pin-controller/i2c0_sleep' defined in zephyr/boards/u-blox/ubx_bmd330eval/ubx_bmd330eval_nrf52810-pinctrl.dtsi:33 */
		i2c0_sleep: i2c0_sleep {
			phandle = < 0x5 >; /* in zephyr/boards/u-blox/ubx_bmd330eval/ubx_bmd330eval_nrf52810.dts:178 */

			/* node '/pin-controller/i2c0_sleep/group1' defined in zephyr/boards/u-blox/ubx_bmd330eval/ubx_bmd330eval_nrf52810-pinctrl.dtsi:34 */
			group1 {
				psels = < 0xc00001a >,
				        < 0xb00001b >; /* in zephyr/boards/u-blox/ubx_bmd330eval/ubx_bmd330eval_nrf52810-pinctrl.dtsi:35 */
				low-power-enable;      /* in zephyr/boards/u-blox/ubx_bmd330eval/ubx_bmd330eval_nrf52810-pinctrl.dtsi:37 */
			};
		};

		/* node '/pin-controller/pwm0_default' defined in zephyr/boards/u-blox/ubx_bmd330eval/ubx_bmd330eval_nrf52810-pinctrl.dtsi:41 */
		pwm0_default: pwm0_default {
			phandle = < 0x9 >; /* in zephyr/boards/u-blox/ubx_bmd330eval/ubx_bmd330eval_nrf52810.dts:184 */

			/* node '/pin-controller/pwm0_default/group1' defined in zephyr/boards/u-blox/ubx_bmd330eval/ubx_bmd330eval_nrf52810-pinctrl.dtsi:42 */
			group1 {
				psels = < 0x16000011 >; /* in zephyr/boards/u-blox/ubx_bmd330eval/ubx_bmd330eval_nrf52810-pinctrl.dtsi:43 */
				nordic,invert;          /* in zephyr/boards/u-blox/ubx_bmd330eval/ubx_bmd330eval_nrf52810-pinctrl.dtsi:44 */
			};
		};

		/* node '/pin-controller/pwm0_sleep' defined in zephyr/boards/u-blox/ubx_bmd330eval/ubx_bmd330eval_nrf52810-pinctrl.dtsi:48 */
		pwm0_sleep: pwm0_sleep {
			phandle = < 0xa >; /* in zephyr/boards/u-blox/ubx_bmd330eval/ubx_bmd330eval_nrf52810.dts:185 */

			/* node '/pin-controller/pwm0_sleep/group1' defined in zephyr/boards/u-blox/ubx_bmd330eval/ubx_bmd330eval_nrf52810-pinctrl.dtsi:49 */
			group1 {
				psels = < 0x16000011 >; /* in zephyr/boards/u-blox/ubx_bmd330eval/ubx_bmd330eval_nrf52810-pinctrl.dtsi:50 */
				low-power-enable;       /* in zephyr/boards/u-blox/ubx_bmd330eval/ubx_bmd330eval_nrf52810-pinctrl.dtsi:51 */
			};
		};

		/* node '/pin-controller/spi0_default' defined in zephyr/boards/u-blox/ubx_bmd330eval/ubx_bmd330eval_nrf52810-pinctrl.dtsi:55 */
		spi0_default: spi0_default {
			phandle = < 0x7 >; /* in zephyr/boards/u-blox/ubx_bmd330eval/ubx_bmd330eval_nrf52810.dts:193 */

			/* node '/pin-controller/spi0_default/group1' defined in zephyr/boards/u-blox/ubx_bmd330eval/ubx_bmd330eval_nrf52810-pinctrl.dtsi:56 */
			group1 {
				psels = < 0x4000019 >,
				        < 0x5000017 >,
				        < 0x6000018 >; /* in zephyr/boards/u-blox/ubx_bmd330eval/ubx_bmd330eval_nrf52810-pinctrl.dtsi:57 */
			};
		};

		/* node '/pin-controller/spi0_sleep' defined in zephyr/boards/u-blox/ubx_bmd330eval/ubx_bmd330eval_nrf52810-pinctrl.dtsi:63 */
		spi0_sleep: spi0_sleep {
			phandle = < 0x8 >; /* in zephyr/boards/u-blox/ubx_bmd330eval/ubx_bmd330eval_nrf52810.dts:194 */

			/* node '/pin-controller/spi0_sleep/group1' defined in zephyr/boards/u-blox/ubx_bmd330eval/ubx_bmd330eval_nrf52810-pinctrl.dtsi:64 */
			group1 {
				psels = < 0x4000019 >,
				        < 0x5000017 >,
				        < 0x6000018 >; /* in zephyr/boards/u-blox/ubx_bmd330eval/ubx_bmd330eval_nrf52810-pinctrl.dtsi:65 */
				low-power-enable;      /* in zephyr/boards/u-blox/ubx_bmd330eval/ubx_bmd330eval_nrf52810-pinctrl.dtsi:68 */
			};
		};
	};

	/* node '/entropy_bt_hci' defined in zephyr/dts/vendor/nordic/nrf_common.dtsi:34 */
	rng_hci: entropy_bt_hci {
		compatible = "zephyr,bt-hci-entropy"; /* in zephyr/dts/vendor/nordic/nrf_common.dtsi:35 */
		status = "disabled";                  /* in zephyr/dts/vendor/nordic/nrf_common.dtsi:36 */
	};

	/* node '/sw-pwm' defined in zephyr/dts/vendor/nordic/nrf_common.dtsi:39 */
	sw_pwm: sw-pwm {
		compatible = "nordic,nrf-sw-pwm"; /* in zephyr/dts/vendor/nordic/nrf_common.dtsi:40 */
		status = "disabled";              /* in zephyr/dts/vendor/nordic/nrf_common.dtsi:41 */
		generator = < &timer1 >;          /* in zephyr/dts/vendor/nordic/nrf_common.dtsi:42 */
		clock-prescaler = < 0x0 >;        /* in zephyr/dts/vendor/nordic/nrf_common.dtsi:43 */
		#pwm-cells = < 0x3 >;             /* in zephyr/dts/vendor/nordic/nrf_common.dtsi:44 */
	};

	/* node '/cpus' defined in zephyr/dts/arm/nordic/nrf52810.dtsi:15 */
	cpus {
		#address-cells = < 0x1 >; /* in zephyr/dts/arm/nordic/nrf52810.dtsi:16 */
		#size-cells = < 0x0 >;    /* in zephyr/dts/arm/nordic/nrf52810.dtsi:17 */

		/* node '/cpus/cpu@0' defined in zephyr/dts/arm/nordic/nrf52810.dtsi:19 */
		cpu@0 {
			device_type = "cpu";          /* in zephyr/dts/arm/nordic/nrf52810.dtsi:20 */
			compatible = "arm,cortex-m4"; /* in zephyr/dts/arm/nordic/nrf52810.dtsi:21 */
			reg = < 0x0 >;                /* in zephyr/dts/arm/nordic/nrf52810.dtsi:22 */
			#address-cells = < 0x1 >;     /* in zephyr/dts/arm/nordic/nrf52810.dtsi:23 */
			#size-cells = < 0x1 >;        /* in zephyr/dts/arm/nordic/nrf52810.dtsi:24 */

			/* node '/cpus/cpu@0/itm@e0000000' defined in zephyr/dts/arm/nordic/nrf52810.dtsi:26 */
			itm: itm@e0000000 {
				compatible = "arm,armv7m-itm";     /* in zephyr/dts/arm/nordic/nrf52810.dtsi:27 */
				reg = < 0xe0000000 0x1000 >;       /* in zephyr/dts/arm/nordic/nrf52810.dtsi:28 */
				swo-ref-frequency = < 0x1e84800 >; /* in zephyr/dts/arm/nordic/nrf52810.dtsi:29 */
			};
		};
	};

	/* node '/clocks' defined in zephyr/dts/arm/nordic/nrf52810.dtsi:34 */
	clocks {

		/* node '/clocks/hfxo' defined in zephyr/dts/arm/nordic/nrf52810.dtsi:35 */
		hfxo: hfxo {
			compatible = "nordic,nrf52-hfxo"; /* in zephyr/dts/arm/nordic/nrf52810.dtsi:36 */
			clock-frequency = < 0x3d09000 >;  /* in zephyr/dts/arm/nordic/nrf52810.dtsi:37 */
			startup-time-us = < 0x578 >;      /* in zephyr/dts/arm/nordic/nrf52810.dtsi:38 */
			#clock-cells = < 0x0 >;           /* in zephyr/dts/arm/nordic/nrf52810.dtsi:39 */
		};
	};

	/* node '/leds' defined in zephyr/boards/u-blox/ubx_bmd330eval/ubx_bmd330eval_nrf52810.dts:28 */
	leds {
		compatible = "gpio-leds"; /* in zephyr/boards/u-blox/ubx_bmd330eval/ubx_bmd330eval_nrf52810.dts:29 */

		/* node '/leds/led_0' defined in zephyr/boards/u-blox/ubx_bmd330eval/ubx_bmd330eval_nrf52810.dts:31 */
		led0: led_0 {
			gpios = < &gpio0 0x11 0x1 >; /* in zephyr/boards/u-blox/ubx_bmd330eval/ubx_bmd330eval_nrf52810.dts:32 */
			label = "Red LED 0";         /* in zephyr/boards/u-blox/ubx_bmd330eval/ubx_bmd330eval_nrf52810.dts:33 */
		};

		/* node '/leds/led_1' defined in zephyr/boards/u-blox/ubx_bmd330eval/ubx_bmd330eval_nrf52810.dts:36 */
		led1: led_1 {
			gpios = < &gpio0 0x12 0x1 >; /* in zephyr/boards/u-blox/ubx_bmd330eval/ubx_bmd330eval_nrf52810.dts:37 */
			label = "Red LED 1";         /* in zephyr/boards/u-blox/ubx_bmd330eval/ubx_bmd330eval_nrf52810.dts:38 */
		};

		/* node '/leds/led_2' defined in zephyr/boards/u-blox/ubx_bmd330eval/ubx_bmd330eval_nrf52810.dts:41 */
		led2: led_2 {
			gpios = < &gpio0 0x13 0x1 >; /* in zephyr/boards/u-blox/ubx_bmd330eval/ubx_bmd330eval_nrf52810.dts:42 */
			label = "Green LED 2";       /* in zephyr/boards/u-blox/ubx_bmd330eval/ubx_bmd330eval_nrf52810.dts:43 */
		};

		/* node '/leds/led_3' defined in zephyr/boards/u-blox/ubx_bmd330eval/ubx_bmd330eval_nrf52810.dts:46 */
		led3: led_3 {
			gpios = < &gpio0 0x14 0x1 >; /* in zephyr/boards/u-blox/ubx_bmd330eval/ubx_bmd330eval_nrf52810.dts:47 */
			label = "Green LED 3";       /* in zephyr/boards/u-blox/ubx_bmd330eval/ubx_bmd330eval_nrf52810.dts:48 */
		};
	};

	/* node '/pwmleds' defined in zephyr/boards/u-blox/ubx_bmd330eval/ubx_bmd330eval_nrf52810.dts:52 */
	pwmleds {
		compatible = "pwm-leds"; /* in zephyr/boards/u-blox/ubx_bmd330eval/ubx_bmd330eval_nrf52810.dts:53 */

		/* node '/pwmleds/pwm_led_0' defined in zephyr/boards/u-blox/ubx_bmd330eval/ubx_bmd330eval_nrf52810.dts:55 */
		pwm_led0: pwm_led_0 {
			pwms = < &pwm0 0x0 0x1312d00 0x1 >; /* in zephyr/boards/u-blox/ubx_bmd330eval/ubx_bmd330eval_nrf52810.dts:56 */
		};
	};

	/* node '/buttons' defined in zephyr/boards/u-blox/ubx_bmd330eval/ubx_bmd330eval_nrf52810.dts:60 */
	buttons {
		compatible = "gpio-keys"; /* in zephyr/boards/u-blox/ubx_bmd330eval/ubx_bmd330eval_nrf52810.dts:61 */

		/* node '/buttons/button_0' defined in zephyr/boards/u-blox/ubx_bmd330eval/ubx_bmd330eval_nrf52810.dts:63 */
		button0: button_0 {
			gpios = < &gpio0 0xd 0x11 >;    /* in zephyr/boards/u-blox/ubx_bmd330eval/ubx_bmd330eval_nrf52810.dts:64 */
			label = "Push button switch 0"; /* in zephyr/boards/u-blox/ubx_bmd330eval/ubx_bmd330eval_nrf52810.dts:65 */
			zephyr,code = < 0xb >;          /* in zephyr/boards/u-blox/ubx_bmd330eval/ubx_bmd330eval_nrf52810.dts:66 */
		};

		/* node '/buttons/button_1' defined in zephyr/boards/u-blox/ubx_bmd330eval/ubx_bmd330eval_nrf52810.dts:69 */
		button1: button_1 {
			gpios = < &gpio0 0xe 0x11 >;    /* in zephyr/boards/u-blox/ubx_bmd330eval/ubx_bmd330eval_nrf52810.dts:70 */
			label = "Push button switch 1"; /* in zephyr/boards/u-blox/ubx_bmd330eval/ubx_bmd330eval_nrf52810.dts:71 */
			zephyr,code = < 0x2 >;          /* in zephyr/boards/u-blox/ubx_bmd330eval/ubx_bmd330eval_nrf52810.dts:72 */
		};

		/* node '/buttons/button_2' defined in zephyr/boards/u-blox/ubx_bmd330eval/ubx_bmd330eval_nrf52810.dts:75 */
		button2: button_2 {
			gpios = < &gpio0 0xf 0x11 >;    /* in zephyr/boards/u-blox/ubx_bmd330eval/ubx_bmd330eval_nrf52810.dts:76 */
			label = "Push button switch 2"; /* in zephyr/boards/u-blox/ubx_bmd330eval/ubx_bmd330eval_nrf52810.dts:77 */
			zephyr,code = < 0x3 >;          /* in zephyr/boards/u-blox/ubx_bmd330eval/ubx_bmd330eval_nrf52810.dts:78 */
		};

		/* node '/buttons/button_3' defined in zephyr/boards/u-blox/ubx_bmd330eval/ubx_bmd330eval_nrf52810.dts:81 */
		button3: button_3 {
			gpios = < &gpio0 0x10 0x11 >;   /* in zephyr/boards/u-blox/ubx_bmd330eval/ubx_bmd330eval_nrf52810.dts:82 */
			label = "Push button switch 3"; /* in zephyr/boards/u-blox/ubx_bmd330eval/ubx_bmd330eval_nrf52810.dts:83 */
			zephyr,code = < 0x4 >;          /* in zephyr/boards/u-blox/ubx_bmd330eval/ubx_bmd330eval_nrf52810.dts:84 */
		};
	};

	/* node '/connector' defined in zephyr/boards/u-blox/ubx_bmd330eval/ubx_bmd330eval_nrf52810.dts:88 */
	arduino_header: connector {
		compatible = "arduino-header-r3";          /* in zephyr/boards/u-blox/ubx_bmd330eval/ubx_bmd330eval_nrf52810.dts:89 */
		#gpio-cells = < 0x2 >;                     /* in zephyr/boards/u-blox/ubx_bmd330eval/ubx_bmd330eval_nrf52810.dts:90 */
		gpio-map-mask = < 0xffffffff 0xffffffc0 >; /* in zephyr/boards/u-blox/ubx_bmd330eval/ubx_bmd330eval_nrf52810.dts:91 */
		gpio-map-pass-thru = < 0x0 0x3f >;         /* in zephyr/boards/u-blox/ubx_bmd330eval/ubx_bmd330eval_nrf52810.dts:92 */
		gpio-map = < 0x0 0x0 &gpio0 0x3 0x0 >,
		           < 0x1 0x0 &gpio0 0x4 0x0 >,
		           < 0x2 0x0 &gpio0 0x1c 0x0 >,
		           < 0x3 0x0 &gpio0 0x1d 0x0 >,
		           < 0x4 0x0 &gpio0 0x1e 0x0 >,
		           < 0x5 0x0 &gpio0 0x1f 0x0 >,
		           < 0x6 0x0 &gpio0 0xb 0x0 >,
		           < 0x7 0x0 &gpio0 0xc 0x0 >,
		           < 0x8 0x0 &gpio0 0xd 0x0 >,
		           < 0x9 0x0 &gpio0 0xe 0x0 >,
		           < 0xa 0x0 &gpio0 0xf 0x0 >,
		           < 0xb 0x0 &gpio0 0x10 0x0 >,
		           < 0xc 0x0 &gpio0 0x11 0x0 >,
		           < 0xd 0x0 &gpio0 0x12 0x0 >,
		           < 0xe 0x0 &gpio0 0x13 0x0 >,
		           < 0xf 0x0 &gpio0 0x14 0x0 >,
		           < 0x10 0x0 &gpio0 0x16 0x0 >,
		           < 0x11 0x0 &gpio0 0x17 0x0 >,
		           < 0x12 0x0 &gpio0 0x18 0x0 >,
		           < 0x13 0x0 &gpio0 0x19 0x0 >,
		           < 0x14 0x0 &gpio0 0x1a 0x0 >,
		           < 0x15 0x0 &gpio0 0x1b 0x0 >;   /* in zephyr/boards/u-blox/ubx_bmd330eval/ubx_bmd330eval_nrf52810.dts:93 */
		phandle = < 0x6 >;                         /* in zephyr/boards/u-blox/ubx_bmd330eval/ubx_bmd330eval_nrf52810.dts:192 */
	};

	/* node '/analog-connector' defined in zephyr/boards/u-blox/ubx_bmd330eval/ubx_bmd330eval_nrf52810.dts:117 */
	arduino_adc: analog-connector {
		compatible = "arduino,uno-adc";    /* in zephyr/boards/u-blox/ubx_bmd330eval/ubx_bmd330eval_nrf52810.dts:118 */
		#io-channel-cells = < 0x1 >;       /* in zephyr/boards/u-blox/ubx_bmd330eval/ubx_bmd330eval_nrf52810.dts:119 */
		io-channel-map = < 0x0 &adc 0x1 >,
		                 < 0x1 &adc 0x2 >,
		                 < 0x2 &adc 0x4 >,
		                 < 0x3 &adc 0x5 >,
		                 < 0x4 &adc 0x6 >,
		                 < 0x5 &adc 0x7 >; /* in zephyr/boards/u-blox/ubx_bmd330eval/ubx_bmd330eval_nrf52810.dts:120 */
	};
};
